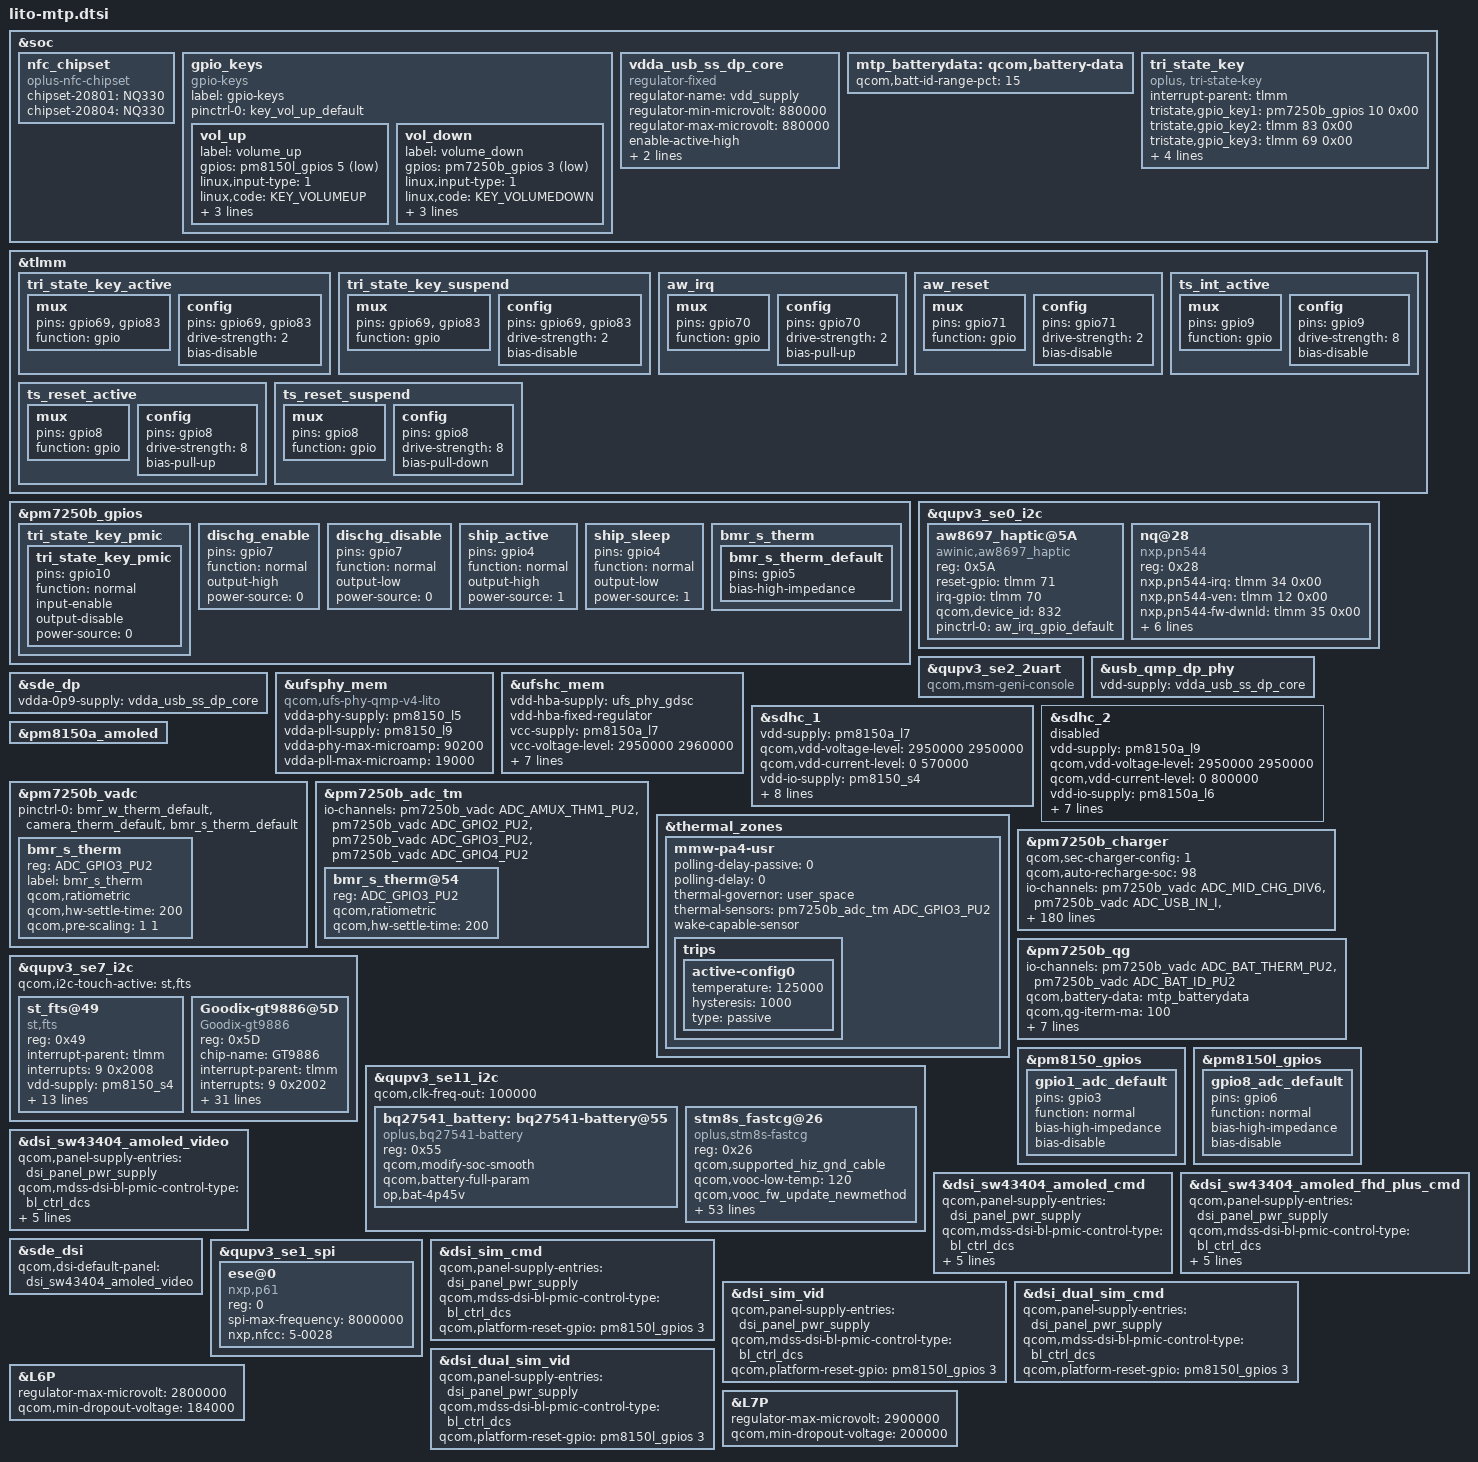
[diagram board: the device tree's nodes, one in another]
#include <dt-bindings/gpio/gpio.h>
#include "lito-audio-overlay.dtsi"
#include "lito-pmic-overlay.dtsi"
#include "lito-sde-display.dtsi"
#include "lito-thermal-overlay.dtsi"
#include "lito-20801-sensor.dtsi"

&soc {
    //add for nfc_chipset
	nfc_chipset {
		compatible = "oplus-nfc-chipset";
		chipset-20801 = "NQ330";
		chipset-20804 = "NQ330";
	};
	gpio_keys {
		compatible = "gpio-keys";
		label = "gpio-keys";

		pinctrl-names = "default";
		pinctrl-0 = <&key_vol_up_default>;

		vol_up {
			label = "volume_up";
			gpios = <&pm8150l_gpios 5 GPIO_ACTIVE_LOW>;
			linux,input-type = <1>;
			linux,code = <KEY_VOLUMEUP>;
			gpio-key,wakeup;
			debounce-interval = <15>;
			linux,can-disable;
		};

               vol_down {
                        label = "volume_down";
                        gpios = <&pm7250b_gpios  3 GPIO_ACTIVE_LOW>;
                        linux,input-type = <1>;
                        linux,code = <KEY_VOLUMEDOWN>;
                        gpio-key,wakeup;
                        debounce-interval = <15>;
                        linux,can-disable;
                };

	};

	vdda_usb_ss_dp_core: vdda_usb_ss_dp_core {
		compatible = "regulator-fixed";
		regulator-name = "vdd_supply";
		regulator-min-microvolt = <880000>;
		regulator-max-microvolt = <880000>;
		enable-active-high;
		gpio = <&pm8150l_gpios 12 GPIO_ACTIVE_HIGH>;
		pinctrl-names = "default";
		pinctrl-0 = <&usb_eldo13>;
	};

	mtp_batterydata: qcom,battery-data {
		qcom,batt-id-range-pct = <15>;
		#include "qg-batterydata-alium-3600mah.dtsi"
		#include "qg-batterydata-atl466271_3300mAh.dtsi"
	};
	
	tri_state_key:tri_state_key {
		compatible = "oplus, tri-state-key";
		status = "ok";
		interrupt-parent = <&tlmm>;
		tristate,gpio_key1 = <&pm7250b_gpios 10 0x00>;
		tristate,gpio_key2 = <&tlmm 83 0x00>;
		tristate,gpio_key3 = <&tlmm 69 0x00>;
		pinctrl-names =
					"pmx_tri_state_key_active",
					"pmx_tri_state_key_suspend";
		pinctrl-0 = <&tri_state_key_active &tri_state_key_pmic>;
		pinctrl-1 = <&tri_state_key_suspend &tri_state_key_pmic>;
	};
};


&tlmm{
	tri_state_key_active: tri_state_key_active {
		mux {
			pins = "gpio69", "gpio83";
			function = "gpio";
		};
		config {
			pins = "gpio69", "gpio83";
			drive-strength = <2>;
			bias-disable;
		};
	};

	tri_state_key_suspend: tri_state_key_suspend {
		mux {
			pins = "gpio69", "gpio83";
			function = "gpio";
		};
		config {
			pins = "gpio69", "gpio83";
			drive-strength = <2>;
			bias-disable;
		};
	};
};

&pm7250b_gpios {
	tri_state_key_pmic {
		tri_state_key_pmic: tri_state_key_pmic {
			pins = "gpio10";
			function = "normal";
			input-enable;
			output-disable;
			power-source = <0>;
		};
	};

        dischg_enable: dischg_enable {
                        pins = "gpio7";
                        function = "normal";
                        output-high;
                        power-source = <0>;
        };

        dischg_disable: dischg_disable {
                        pins = "gpio7";
                        function = "normal";
                        output-low;
                        power-source = <0>;
        };

        ship_active: ship_active {
                        pins = "gpio4";
                        function = "normal";
                        output-high;
                        power-source = <1>;     /* 1.8V input supply */
        };

        ship_sleep: ship_sleep {
                        pins = "gpio4";
                        function = "normal";
                        output-low;
                        power-source = <1>;     /* 1.8V input supply */
        };
};


/*for aw haptic start*/

&tlmm {
       aw_irq: aw_irq {
       mux {
            pins = "gpio70";
            function = "gpio";
       };
       config {
               pins = "gpio70";
               drive-strength = <2>;
               bias-pull-up;
       };
    };
    aw_reset: aw_reset {
       mux {
	            pins = "gpio71";
	            function = "gpio";
	       };
	      config {
	              pins = "gpio71";
	              drive-strength = <2>;
	              bias-disable;
	      };
      };
};
&qupv3_se0_i2c {
	status = "ok";
	aw8697_haptic@5A {
		compatible = "awinic,aw8697_haptic";
		reg = <0x5A>;
		reset-gpio = <&tlmm 71 0x00>;
		irq-gpio = <&tlmm 70 0x00>;
		pinctrl-names = "default";
		qcom,device_id = <832>;

		pinctrl-0 = <&aw_irq_gpio_default>;
		status = "okay";
	};
};

&qupv3_se2_2uart {
    compatible = "qcom,msm-geni-console";
};

&usb_qmp_dp_phy {
	vdd-supply = <&vdda_usb_ss_dp_core>;
};

&sde_dp {
	vdda-0p9-supply = <&vdda_usb_ss_dp_core>;
};

&ufsphy_mem {
	compatible = "qcom,ufs-phy-qmp-v4-lito";

	vdda-phy-supply = <&pm8150_l5>;
	vdda-pll-supply = <&pm8150_l9>;
	vdda-phy-max-microamp = <90200>;
	vdda-pll-max-microamp = <19000>;

	status = "ok";
};

&ufshc_mem {
	vdd-hba-supply = <&ufs_phy_gdsc>;
	vdd-hba-fixed-regulator;
	vcc-supply = <&pm8150a_l7>;
	vcc-voltage-level = <2950000 2960000>;
	vccq2-supply = <&pm8150_s4>;
	vcc-max-microamp = <800000>;
	vccq2-max-microamp = <800000>;

	qcom,vddp-ref-clk-supply = <&pm8150_l9>;
	qcom,vddp-ref-clk-max-microamp = <100>;
	qcom,vddp-ref-clk-min-uV = <1152000>;
	qcom,vddp-ref-clk-max-uV = <1200000>;
	status = "ok";
};

&sdhc_1 {
	vdd-supply = <&pm8150a_l7>;
	qcom,vdd-voltage-level = <2950000 2950000>;
	qcom,vdd-current-level = <0 570000>;

	vdd-io-supply = <&pm8150_s4>;
	qcom,vdd-io-always-on;
	qcom,vdd-io-lpm-sup;
	qcom,vdd-io-voltage-level = <1800000 1800000>;
	qcom,vdd-io-current-level = <0 325000>;

	pinctrl-names = "active", "sleep";
	pinctrl-0 = <&sdc1_clk_on &sdc1_cmd_on &sdc1_data_on
					&sdc1_rclk_on>;
	pinctrl-1 = <&sdc1_clk_off &sdc1_cmd_off &sdc1_data_off
					&sdc1_rclk_off>;

	status = "ok";
};

&sdhc_2 {
	vdd-supply = <&pm8150a_l9>;
	qcom,vdd-voltage-level = <2950000 2950000>;
	qcom,vdd-current-level = <0 800000>;

	vdd-io-supply = <&pm8150a_l6>;
	qcom,vdd-io-voltage-level = <1800000 2950000>;
	qcom,vdd-io-current-level = <0 22000>;

	pinctrl-names = "active", "sleep";
	pinctrl-0 = <&sdc2_clk_on  &sdc2_cmd_on &sdc2_data_on &sdc2_cd_on>;
	pinctrl-1 = <&sdc2_clk_off &sdc2_cmd_off &sdc2_data_off &sdc2_cd_off>;

	cd-gpios = <&tlmm 69 GPIO_ACTIVE_LOW>;

	status = "disabled";
};

&pm8150a_amoled {
	status = "ok";
};

&pm7250b_vadc {
	pinctrl-0 = <
		&bmr_w_therm_default
		&camera_therm_default
		&bmr_s_therm_default
	>;

	bmr_s_therm {
		reg = <ADC_GPIO3_PU2>;
		label = "bmr_s_therm";
		qcom,ratiometric;
		qcom,hw-settle-time = <200>;
		qcom,pre-scaling = <1 1>;
	};
};

&pm7250b_gpios {
	bmr_s_therm {
		bmr_s_therm_default: bmr_s_therm_default {
			pins = "gpio5";
			bias-high-impedance;
		};
	};
};

&pm7250b_adc_tm {
	io-channels = <&pm7250b_vadc ADC_AMUX_THM1_PU2>,
			<&pm7250b_vadc ADC_GPIO2_PU2>,
			<&pm7250b_vadc ADC_GPIO3_PU2>,
			<&pm7250b_vadc ADC_GPIO4_PU2>;

	bmr_s_therm@54 {
		reg = <ADC_GPIO3_PU2>;
		qcom,ratiometric;
		qcom,hw-settle-time = <200>;
	};
};

&thermal_zones {
	mmw-pa4-usr {
		polling-delay-passive = <0>;
		polling-delay = <0>;
		thermal-governor = "user_space";
		thermal-sensors = <&pm7250b_adc_tm ADC_GPIO3_PU2>;
		wake-capable-sensor;
		trips {
			active-config0 {
				temperature = <125000>;
				hysteresis = <1000>;
				type = "passive";
			};
		};
	};
};

&pm7250b_charger {
        status = "ok";
        qcom,sec-charger-config = <1>;
        qcom,auto-recharge-soc = <98>;
        io-channels = <&pm7250b_vadc ADC_MID_CHG_DIV6>,
                      <&pm7250b_vadc ADC_USB_IN_I>,
                      <&pm7250b_vadc ADC_SBUx>,
                      <&pm7250b_vadc ADC_VPH_PWR>,
		      <&pm7250b_vadc ADC_CHG_TEMP>,
		      <&pm7250b_vadc ADC_DIE_TEMP>,
		      <&pm7250b_vadc ADC_AMUX_THM3_PU2>,
                      <&pm7250b_vadc ADC_USB_IN_V_16>,
		      <&pm8150l_vadc ADC_GPIO3_PU2>,
 		      <&pm8150_vadc ADC_GPIO1_PU1>,
 		      <&pm8150l_vadc ADC_GPIO2_PU1>;

        io-channel-names = "mid_voltage",
                           "usb_in_current",
                           "sbux_res",
                           "vph_voltage",
                           "chg_temp",
                           "die_temp",
                           "conn_temp",
                           "usb_in_voltage",
			   "skin_therm",
                           "usb_temp_l",
                           "usb_temp_r";

        qcom,battery-data = <&mtp_batterydata>;
        //qcom,step-charging-enable;
        //qcom,sw-jeita-enable;
        //qcom,wd-bark-time-secs = <16>;
        //qcom,suspend-input-on-debug-batt;
        //qcom,fcc-stepping-enable;
        qcom,smb-internal-pull-kohm = <0>;
        op,low-voltage-charger;
};



/*&pm7250b_charger {
	status = "ok";
	io-channels = <&pm7250b_vadc ADC_USB_IN_V_16>,
		      <&pm7250b_vadc ADC_USB_IN_I>,
		      <&pm7250b_vadc ADC_CHG_TEMP>,
		      <&pm7250b_vadc ADC_DIE_TEMP>,
		      <&pm7250b_vadc ADC_AMUX_THM3_PU2>,
		      <&pm7250b_vadc ADC_SBUx>,
		      <&pm7250b_vadc ADC_VPH_PWR>,
		      <&pm7250b_vadc ADC_AMUX_THM1_PU2>;
	io-channel-names = "usb_in_voltage",
			   "usb_in_current",
			   "chg_temp",
			   "die_temp",
			   "conn_temp",
			   "sbux_res",
			   "vph_voltage",
			   "skin_temp";
	qcom,battery-data = <&mtp_batterydata>;
	qcom,sec-charger-config = <1>;
	qcom,auto-recharge-soc = <98>;
	qcom,step-charging-enable;
	qcom,sw-jeita-enable;
	qcom,charger-temp-max = <800>;
	qcom,smb-temp-max = <800>;
	qcom,suspend-input-on-debug-batt;
	qcom,fcc-stepping-enable;
	qcom,fcc-step-delay-ms = <100>;
	qcom,fcc-step-size-ua = <100000>;
	qcom,smb-internal-pull-kohm = <0>;
	qcom,en-skin-therm-mitigation;
	qcom,hvdcp3-standalone-config;
};
*/

&pm7250b_qg {
	status = "ok";
	io-channels = <&pm7250b_vadc ADC_BAT_THERM_PU2>,
		      <&pm7250b_vadc ADC_BAT_ID_PU2>;
	io-channel-names = "batt-therm",
			   "batt-id";
	qcom,battery-data = <&mtp_batterydata>;
	qcom,qg-iterm-ma = <100>;
	qcom,hold-soc-while-full;
	qcom,linearize-soc;
	qcom,cl-feedback-on;
	qcom,tcss-enable;
	qcom,fvss-enable;
	qcom,fvss-vbatt-mv = <3300>;
	qcom,bass-enable;
};

&qupv3_se7_i2c {
	#address-cells = <1>;
	#size-cells = <0>;

	status = "ok";
	qcom,i2c-touch-active = "st,fts";

	st_fts@49 {
		compatible = "st,fts";
		reg = <0x49>;
		interrupt-parent = <&tlmm>;
		interrupts = <9 0x2008>;
		vdd-supply = <&pm8150_s4>;
		avdd-supply = <&pm8150_l13>;
		pinctrl-names = "pmx_ts_active", "pmx_ts_suspend";
		pinctrl-0 = <&ts_active>;
		pinctrl-1 = <&ts_int_suspend &ts_reset_suspend>;
		st,irq-gpio = <&tlmm 9 0x2008>;
		st,reset-gpio = <&tlmm 8 0x00>;
		st,regulator_dvdd = "vdd";
		st,regulator_avdd = "avdd";
		st,x-flip = <1>;
		st,y-flip = <1>;
		st,power_on_suspend;
		panel = <&dsi_sw43404_amoled_cmd &dsi_sw43404_amoled_video
			 &dsi_sw43404_amoled_fhd_plus_cmd>;
	};
};

&qupv3_se7_i2c {
        status = "ok";
        Goodix-gt9886@5D {
                compatible = "Goodix-gt9886";
                reg = <0x5D>;
                chip-name = "GT9886";

                /* Interrupt && Irq-gpio */
                interrupt-parent = <&tlmm>;
                interrupts = <9 0x2002>;

                /* Power Config */
                vdd_2v8-supply = <&pm8150_l13>;
                vdd_2v8_volt = <3008000>;
		enable1v8_gpio = <&pm8150l_gpios 1 GPIO_ACTIVE_LOW>;

               	/* Other HW Resource */
                irq-gpio = <&tlmm 9 0x2002>;
                reset-gpio = <&tlmm 8 0x1>;
                pinctrl-names = "pin_set_high", "pin_set_low";
                pinctrl-0 = <&ts_int_active &ts_reset_active>;
                pinctrl-1 = <&ts_reset_suspend>;

                touchpanel,max-num-support = <10>;
                touchpanel,tx-rx-num = <15 34>;
                touchpanel,panel-coords = <1080 2400>;
                touchpanel,display-coords = <1080 2400>;

		tp_type = <8>;
		platform_support_project = <20801 20804>;
                platform_support_project_dir = <20801 20801>;
                platform_support_project_commandline = "default_commandline", "default_commandline";

                /* SW Support Feature Control */
                black_gesture_support;
                game_switch_support;
                fw_edge_limit_support;
		pressure_report_support;
		charger_pump_support;
		smart_gesture_support;
                fw_update_app_support;
                fingerprint_underscreen_support;
                esd_handle_support;
		register-is-16bit;
		disable_suspend_irq_handler_support;
		irq_need_dev_resume_ok;

				/*
                 *Virtual Key Config:
                 *1:touchpanel,button-type: <virtualkey_type  supportted_button-map>
                 *virtualkey_type:
                 *Type 1: using board_properties
                 *Type 2: using same IC (button zone&& touch zone are seprate)
                 *Type 3: using diffrent IC (button zone&& touch zone are seprate)
                 *Type 4: No need of virtual key process
                 *supportted_button-map:select|menu|home|back
                 *
                 *2:touchpanel,button-map
                 *type (X1,Y1)(X2,Y2)(X3,Y3)(Width_X,Hight_Y)--Only when button-type is 0
                 */
                touchpanel,button-type = <4>;
                touchpanel.button-TRx = <0 0>;

	};
};

&qupv3_se11_i2c {
        status = "ok";
        qcom,clk-freq-out = <100000>;
        bq27541_battery:bq27541-battery@55 {
                status = "ok";
                compatible = "oplus,bq27541-battery";
                reg = <0x55>;
                qcom,modify-soc-smooth;
                qcom,battery-full-param;//only for wite battery full param in guage dirver probe on 7250 platform
                op,bat-4p45v;
        };

        stm8s_fastcg@26{
                status = "okay";
                compatible = "oplus,stm8s-fastcg";
                reg = <0x26>;
		qcom,supported_hiz_gnd_cable;

                qcom,vooc-low-temp = <120>;
		//qcom,oplus_batt_4400mv;
                qcom,vooc_fw_update_newmethod;
                qcom,vooc-high-temp = <430>;
                qcom,vooc-low-soc = <1>;
                qcom,vooc-high-soc = <90>;
                qcom,vooc-fw-type = <0x27>;

                qcom,vooc_multistep_adjust_current_support;
                qcom,vooc_multistep_initial_batt_temp = <310>;
                qcom,vooc_strategy_normal_current = <0x06>;
                qcom,vooc-normal-to-little-cool-current = <0x05>;
                qcom,vooc_batt_over_high_temp = <440>;
                qcom,vooc_batt_over_low_temp = <45>;
                qcom,vooc_over_high_or_low_current = <0x0>;

                qcom,vooc_strategy1_batt_high_temp0 = <425>;
                qcom,vooc_strategy1_batt_high_temp1 = <430>;
                qcom,vooc_strategy1_batt_high_temp2 = <435>;
                qcom,vooc_strategy1_batt_low_temp2 = <420>;
                qcom,vooc_strategy1_batt_low_temp1 = <415>;
                qcom,vooc_strategy1_batt_low_temp0 = <400>;

                qcom,vooc_strategy1_high_current0 = <0x04>;//4A
                qcom,vooc_strategy1_high_current1 = <0x03>;//3A
                qcom,vooc_strategy1_high_current2 = <0x02>;//2A
                qcom,vooc_strategy1_low_current2 = <0x03>;//3A
                qcom,vooc_strategy1_low_current1 = <0x04>;//4A
                qcom,vooc_strategy1_low_current0 = <0x04>;//4A

                qcom,vooc_strategy2_batt_up_temp1 = <375>;
                qcom,vooc_strategy2_batt_up_down_temp2 = <380>;
                qcom,vooc_strategy2_batt_up_temp3 = <390>;
                qcom,vooc_strategy2_batt_up_down_temp4 = <400>;
                qcom,vooc_strategy2_batt_up_temp5 = <410>;
                qcom,vooc_strategy2_batt_up_temp6 = <415>;
                qcom,vooc_strategy2_high0_current = <0x05>;
                qcom,vooc_strategy2_high1_current = <0x04>;
                qcom,vooc_strategy2_high2_current = <0x03>;
                qcom,vooc_strategy2_high3_current = <0x02>;


                pinctrl-names = "switch1_act_switch2_act", "switch1_sleep_switch2_sleep",
                                                "switch1_act_switch3_act", "switch1_sleep_switch3_sleep",
                                                "switch1_act_switch2_sleep", "switch1_sleep_switch2_act",
                                                "clock_active","clock_sleep",
                                                "data_active","data_sleep",
                                                "reset_active","reset_sleep";
                pinctrl-0 = <&charging_switch1_active>;
                pinctrl-1 = <&charging_switch1_sleep >;
                pinctrl-2 = <&charging_switch1_active>;
                pinctrl-3 = <&charging_switch1_sleep >;
                pinctrl-4 = <&charging_switch1_active>;
                pinctrl-5 = <&charging_switch1_sleep>;
                pinctrl-6 = <&charging_clock_active >;
                pinctrl-7 = <&charging_clock_sleep >;
                pinctrl-8 = <&charging_data_active >;
                pinctrl-9 = <&charging_data_sleep >;
                pinctrl-10 = <&charging_reset_active >;
                pinctrl-11 = <&charging_reset_sleep >;

                qcom,charging_switch1-gpio = <&tlmm 4 0x00>;
		qcom,charging_switch1_ctr1-gpio = <&tlmm 126 0x00>;
                //qcom,charging_switch2-gpio = <&tlmm 113 0x00>;
                //qcom,charging_switch3-gpio = <&tlmm 126 0x00>;

                qcom,charging_reset-gpio = <&tlmm 24 0x00>;
                qcom,charging_clock-gpio = <&tlmm 44 0x00>;
                qcom,charging_data-gpio = <&tlmm 45 0x00>;
		qcom,parse_fw_from_dt;
		vooc,firmware_data = [
			00 88 82 00 9D 30 82 00 9E 96 82 00 9E 96 82 00 
			9E 96 82 00 9E 96 82 00 9B 90 82 00 9E 96 82 00 
			9E 7D 20 88 82 00 9E 96 82 00 9E 96 82 00 9E 96 
			82 00 9E 96 82 00 9E 96 82 00 9E 96 82 00 9E 96 
			82 00 96 BD 40 88 82 00 9E 96 82 00 9E 96 82 00 
			9E 96 82 00 9E 96 82 00 9E 96 82 00 9E 96 82 00 
			9E 96 82 00 9E 96 60 88 82 00 9E 96 82 00 9E 96 
			82 00 9E 96 82 00 9E 96 82 00 9E 96 82 00 9E 96 
			82 00 9E 96 82 00 9E 96 80 88 C6 00 77 A1 08 24 
			17 CD 9E 57 B7 00 C6 00 77 5F 97 B6 00 D7 00 56 
			C6 00 77 4C C7 00 77 81 C6 00 A0 88 77 A1 08 27 
			03 CC 89 A9 CD 9D 77 C6 00 56 A1 01 26 41 C6 00 
			57 26 3C C6 00 58 A1 01 26 35 C6 00 C0 88 5A 48 
			48 88 C6 00 59 48 48 48 B7 01 84 BA 01 B7 00 C6 
			00 5B 48 BA 00 CA 00 5C C7 00 79 35 09 00 E0 88 
			77 C6 00 42 26 03 CC 89 A9 C6 00 42 4A C7 00 42 
			CC 89 A9 C6 00 56 26 33 C6 00 57 A1 01 26 2C C6 
			00 89 00 58 A1 01 26 25 C6 00 5A 48 48 88 C6 00 
			59 48 48 48 B7 01 84 BA 01 B7 00 C6 00 5B 48 BA 
			00 CA 20 89 00 5C C7 00 79 35 09 00 77 20 7E C6 
			00 57 B7 00 A1 01 26 3C C6 00 58 26 37 C6 00 59 
			A1 01 26 30 40 89 C6 00 5B 48 48 88 C6 00 5A 48 
			48 48 B7 01 84 BA 01 B7 00 C6 00 5C 48 BA 00 CA 
			00 5D C7 00 79 35 60 89 09 00 77 C6 00 42 27 07 
			C6 00 42 4A C7 00 42 81 3D 00 26 32 C6 00 58 A1 
			01 26 2B C6 00 59 A1 01 80 89 26 24 C6 00 5B 48 
			48 88 C6 00 5A 48 48 48 B7 01 84 BA 01 B7 00 C6 
			00 5C 48 BA 00 CA 00 5D C7 00 A0 89 79 35 09 00 
			77 81 CD 8F 80 C6 00 78 27 03 CC 8E B9 72 5F 00 
			48 72 5F 00 49 72 5F 00 4A 72 5F 00 C0 89 4B 72 
			5F 00 4C 72 5F 00 4D 72 5F 00 4E C6 00 81 A1 02 
			26 10 C6 00 79 4E A4 F0 C7 00 82 35 01 00 E0 89 
			4A CC 8E B9 C6 00 81 A1 01 26 10 C6 00 79 CA 00 
			82 C7 00 82 35 01 00 4A CC 8E B9 C6 00 83 A1 05 
			00 8A 26 2D C6 00 4F C7 00 48 C6 00 50 C7 00 49 
			C6 00 51 C7 00 4A C6 00 52 C7 00 4B C6 00 53 C7 
			00 4C 20 8A C6 00 54 C7 00 4D C6 00 55 C7 00 4E 
			CC 8E B9 C6 00 83 A1 04 26 12 C6 00 79 5F 97 CD 
			99 89 CF 00 40 8A 60 35 01 00 4A CC 8E B9 C6 00 
			83 A1 03 26 1E C6 00 79 5F 97 4F 02 90 CE 00 60 
			BF 00 51 02 BA 00 60 8A 01 51 90 CF 00 60 35 01 
			00 4A CC 8E B9 C6 00 83 A1 02 26 22 C6 00 79 5F 
			97 CD 99 91 90 CE 00 60 80 8A BF 00 51 01 BA 01 
			01 BA 00 01 51 90 CF 00 60 35 01 00 4A CC 8E B9 
			C6 00 83 A1 01 26 2D C6 00 79 A0 8A 90 5F 90 97 
			CE 00 60 90 BF 00 01 BA 01 02 CF 00 60 CD 9E 2C 
			35 01 00 4A CE 00 3A C3 00 60 27 03 C0 8A CC 8E 
			B9 35 01 00 86 CC 8E B9 C6 00 84 27 5D C6 00 84 
			90 5F 90 97 AE 00 07 BF 00 93 CD 99 37 1C E0 8A 
			00 10 90 93 72 A9 FF F9 90 F6 C7 00 48 90 93 72 
			A9 FF FA 90 F6 C7 00 49 90 93 72 A9 FF FB 90 F6 
			00 8B C7 00 4A 90 93 72 A9 FF FC 90 F6 C7 00 4B 
			90 93 72 A9 FF FD 90 F6 C7 00 4C 90 93 72 A9 FF 
			FE 90 20 8B F6 C7 00 4D 5A F6 C7 00 4E CC 8E B9 
			C6 00 79 A1 09 26 11 72 5F 00 81 72 5F 00 83 4F 
			CD 9D 99 35 40 8B 01 00 76 81 72 5F 00 81 72 5F 
			00 83 C6 00 79 27 2B 4A 27 2B 4A 26 03 CC 8D 55 
			4A 26 03 CC 8D 9B 60 8B 4A 26 03 CC 8E 32 4A 26 
			03 CC 8E 7B A0 07 26 03 CC 8E 89 4A 26 03 CC 8E 
			A9 CC 8E B9 CC 8F 80 C6 80 8B 00 42 27 03 CC 8C 
			AA C6 00 44 A1 01 27 03 CD 8F 80 C6 00 75 C7 00 
			48 C6 00 97 27 24 C6 00 9B 26 A0 8B 1F 35 01 00 
			49 35 01 00 4A 35 01 00 4B 72 5F 00 4C 35 01 00 
			4D 72 5F 00 4E 35 01 00 9B CC 8E B9 C0 8B CE 00 
			5E A3 0D 40 2E 03 CC 8C 98 CE 00 5E 1C F2 C0 90 
			AE 00 10 CD 99 55 A3 00 3E 2F 03 AE 00 3D E0 8B 
			C6 00 96 27 13 C6 00 9C 26 0E A3 00 3A 2E 09 AE 
			00 3A 35 01 00 9C 20 16 C6 00 95 27 11 C6 00 9D 
			00 8C 26 0C A3 00 39 2E 07 AE 00 39 35 01 00 9D 
			9F CD 9E 26 A4 01 C7 00 49 9F CD 9E 27 A4 01 C7 
			00 4A 20 8C 9F 47 47 47 A4 01 C7 00 4B 9F 47 47 
			A4 01 C7 00 4C 9F 47 A4 01 C7 00 4D 9F A4 01 C7 
			00 4E CD 9A 40 8C F9 A1 00 26 08 C6 00 8B 26 03 
			CC 8E B9 4F CD 9D 99 35 01 00 8B C6 00 94 26 1F 
			35 01 00 49 35 01 60 8C 00 4A 35 01 00 4B 35 01 
			00 4C 35 01 00 4D 72 5F 00 4E 35 01 00 94 CC 8E 
			B9 72 5F 00 49 72 5F 00 80 8C 4A 72 5F 00 4B 35 
			01 00 4C 72 5F 00 4D 35 01 00 4E 72 5F 00 94 CC 
			8E B9 CE 00 5E A3 0B B8 2F 03 A0 8C CC 8E B9 72 
			5F 00 48 CC 8E B9 C6 00 8B 27 27 C6 00 94 26 17 
			35 01 00 48 35 01 00 49 35 01 00 4D C0 8C 35 01 
			00 4E 35 01 00 94 CC 8E B9 35 01 00 4B 72 5F 00 
			94 CC 8E B9 C6 00 8E 27 26 35 01 00 48 35 E0 8C 
			01 00 49 35 01 00 4A 35 01 00 4B 35 01 00 4C 35 
			01 00 4D 35 01 00 4E C6 00 8E 4A C7 00 8E CC 8E 
			00 8D B9 CE 00 5E A3 0D 4C 2E 03 5F 20 0D CE 00 
			5E 1C F2 B4 90 AE 00 0A CD 99 55 9F CD 9E 25 A4 
			01 C7 20 8D 00 48 9F CD 9E 26 A4 01 C7 00 49 9F 
			CD 9E 27 A4 01 C7 00 4A 9F 47 47 47 A4 01 C7 00 
			4B 9F 47 47 40 8D A4 01 C7 00 4C 9F 47 A4 01 C7 
			00 4D 9F A4 01 C7 00 4E CC 8E B9 C6 00 42 26 0E 
			C6 00 44 A1 02 27 60 8D 03 CD 8F 80 35 01 00 48 
			35 03 00 00 A6 04 CD 98 20 C7 00 9A C6 00 9A A1 
			02 26 07 35 01 00 49 CC 80 8D 8E B9 C6 00 9A A1 
			01 26 0B 35 01 00 49 35 01 00 4A CC 8E B9 35 01 
			00 4A CC 8E B9 C6 00 42 26 4F A0 8D C6 00 44 A1 
			03 27 03 CD 8F 80 C6 00 97 27 13 72 5F 00 4B 72 
			5F 00 4C 72 5F 00 4D 72 5F 00 4E CC C0 8D 8E B9 
			C6 00 98 A1 01 26 13 72 5F 00 4B 72 5F 00 4C 35 
			01 00 4D 72 5F 00 4E CC 8E B9 72 5F 00 4B E0 8D 
			72 5F 00 4C 35 01 00 4D 35 01 00 4E CC 8E B9 C6 
			00 91 CD 9E 20 A4 01 C7 00 49 C6 00 91 4E A4 0F 
			00 8E A4 01 C7 00 4A C6 00 91 44 44 44 A4 01 C7 
			00 4B C6 00 91 44 44 A4 01 C7 00 4C C6 00 91 44 
			A4 01 20 8E C7 00 4D C6 00 91 A4 01 C7 00 4E 72 
			5F 00 8E CC 8E B9 C6 00 43 27 11 C6 00 43 4A C7 
			00 43 35 01 40 8E 00 4A 35 01 00 4E 20 71 C6 00 
			42 27 08 C6 00 75 C7 00 48 20 E9 C6 00 44 A1 04 
			27 03 CD 8F 80 35 60 8E 01 00 45 72 5F 00 46 35 
			01 00 47 C6 00 75 C7 00 48 35 01 00 4A 35 01 00 
			4E 20 3E 35 03 00 81 35 80 8E 01 00 49 35 01 00 
			4B 20 30 C6 00 40 27 2B C6 00 88 27 26 C6 00 40 
			4A C7 00 40 35 06 00 83 CD 9E A0 8E 77 C7 00 8A 
			CD 97 77 20 10 35 07 00 84 35 08 00 85 35 01 00 
			4A 35 01 00 4B C6 00 78 5F 97 D6 00 C0 8E 45 CD 
			9D EB C6 00 78 4C C7 00 78 C6 00 78 A1 0A 24 03 
			CC 8F 7F A6 04 CD 9C 30 CD 9D DE 72 5F 00 E0 8E 
			78 72 5F 00 77 72 5F 00 7A 72 5F 00 73 C6 00 81 
			27 08 C6 00 81 4A C7 00 81 81 C6 00 83 27 08 C6 
			00 8F 00 83 4A C7 00 83 81 C6 00 84 27 0F C6 00 
			84 4A C7 00 84 C6 00 85 4A C7 00 85 81 C6 00 79 
			4A 27 20 8F 4B 4A 27 08 4A 27 45 4A 27 23 20 4A 
			C6 00 9A A1 01 26 4C C6 00 87 A1 01 26 05 A6 01 
			CD 9D 99 72 40 8F 5F 00 9A C6 00 42 26 37 35 03 
			00 44 81 C6 00 42 26 0F C6 00 48 27 06 35 02 00 
			44 20 04 35 04 00 60 8F 44 35 01 00 88 CD 9E 77 
			C7 00 89 81 C6 00 42 26 0E 35 01 00 44 81 C6 00 
			42 26 04 35 04 00 44 81 80 8F C6 00 99 A1 02 27 
			0F C6 00 99 A1 01 26 05 35 02 00 99 81 CD 9E 12 
			81 CD 98 DF CD 98 E4 52 04 4F A0 8F 6B 03 6B 02 
			6B 01 3F 0B 3F 0C 3F 0D 3F 0E 6B 04 3F 0F 3F 0A 
			AE 17 70 CF 00 3C AE 03 84 CF 00 3E C0 8F 20 28 
			A6 0A 97 B6 00 42 41 B7 00 C6 00 8E 26 0E C6 00 
			90 B7 01 C6 00 92 CD 9A B7 C7 00 8E CD 9E E0 8F 
			38 CD 9E 38 AE 17 70 CF 00 6A CD 9E 87 CE 00 6A 
			26 43 A6 58 CD 95 23 B7 00 C6 00 8B 26 E0 B6 00 
			00 90 A1 07 26 0A 4F CD 9D 99 35 01 00 8B 20 D0 
			3D 00 26 05 CD 9E 12 20 C7 A1 06 26 06 35 3B 00 
			00 20 20 90 AA A1 02 26 06 35 19 00 00 20 A0 A1 
			01 26 93 35 14 00 00 20 96 CE 00 68 27 03 CC 90 
			F7 C6 00 7C 40 90 CD 9A 30 BF 08 C6 00 8B 27 03 
			CC 90 E8 A3 F8 30 2E 12 7B 01 4C 6B 01 7B 01 A1 
			04 25 0A A6 54 CD 60 90 9C C0 20 03 4F 6B 01 BE 
			08 A3 1B 59 2F 10 B6 0D 4C B7 0D A1 08 25 09 A6 
			59 CD 9C C0 20 02 3F 0D 80 90 BE 08 A3 01 F4 2E 
			08 CE 00 5E A3 11 31 2E 0F BE 08 A3 03 84 2E 18 
			CE 00 5E A3 11 81 2F 10 B6 0E A0 90 4C B7 0E A1 
			06 25 09 A6 5A CD 9C C0 20 02 3F 0E C6 00 41 A1 
			02 26 2E BE 08 A3 04 B0 2E 27 CE 00 C0 90 5E A3 
			11 8B 2F 05 A6 5A CD 9C C0 CE 00 5E A3 11 81 2F 
			12 7B 02 4C 6B 02 7B 02 A1 06 25 0A A6 5A E0 90 
			CD 9C C0 20 03 4F 6B 02 CD 9E 38 CD 9E 38 AE 03 
			E8 CF 00 68 CC 8F EA CE 00 66 26 36 C6 00 42 26 
			00 91 31 C6 00 7D CD 9A 30 A3 00 60 2F 15 C6 00 
			8B 26 10 B6 0B 4C B7 0B A1 04 25 09 A6 5A CD 9C 
			C0 20 20 91 02 3F 0B CD 9E 38 CD 9E 38 AE 07 D0 
			CF 00 66 CC 8F EA CE 00 64 26 77 C6 00 7B CD 9A 
			30 CF 00 5E 40 91 C6 00 8B 26 5A CE 00 3E 27 08 
			CE 00 5E A3 10 69 2F 0B C6 00 92 A1 33 25 04 35 
			32 00 92 C6 00 8E 60 91 26 13 C6 00 90 B7 01 C6 
			00 8F B7 00 C6 00 92 CD 9A B7 C7 00 8E CE 00 5E 
			A3 11 8B 2F 05 A6 5A CD 80 91 9C C0 CE 00 5E A3 
			11 81 2F 12 7B 03 4C 6B 03 7B 03 A1 06 25 0A A6 
			5A CD 9C C0 20 03 4F 6B 03 CD A0 91 9E 38 CD 9E 
			38 AE 01 F4 CF 00 64 CC 8F EA CE 00 6E 27 03 CC 
			92 4D C6 00 7E CD 9A 30 BF 08 A3 01 C0 91 5F 2F 
			05 1C FF F6 BF 08 C6 00 8B 26 71 BE 08 A3 01 B3 
			2F 13 B6 0A 4C B7 0A A1 03 25 28 35 03 00 E0 91 
			0A 35 01 00 96 20 1E A3 01 A5 2F 15 3F 0A B6 0F 
			4C B7 0F A1 03 25 0E 35 03 00 0F 35 01 00 95 20 
			00 92 04 3F 0F 3F 0A 1C FF 8D A3 01 46 25 10 B6 
			0C 4C B7 0C A1 03 25 28 A6 5C CD 9C C0 20 21 3F 
			0C C6 20 92 00 41 A1 01 26 0D BE 08 A3 01 5F 2F 
			11 35 02 00 41 20 0B BE 08 A3 01 59 2E 04 35 01 
			00 41 CD 9E 40 92 38 CD 9E 38 AE 01 F4 CF 00 6E 
			CC 8F EA CE 00 70 26 33 C6 00 8B 26 18 CD 9A F9 
			A1 00 27 08 4F CD 60 92 9D 99 35 01 00 8B AE 03 
			20 CF 00 70 CC 8F EA 0D 04 26 09 A6 5D CD 95 23 
			A6 01 6B 04 AE 27 10 CF 80 92 00 70 CC 8F EA CE 
			00 6C 27 03 CC 8F EA CE 00 3C 26 0A C6 00 8B 26 
			05 A6 5A CD 9C C0 C6 00 73 26 A0 92 07 C6 00 99 
			A1 02 25 11 C6 00 76 27 07 A6 59 CD 9C C0 20 05 
			A6 54 CD 9C C0 C6 00 76 27 05 A6 59 C0 92 CD 9C 
			C0 AE 00 14 CF 00 6C CC 8F EA CD 9E 82 CD 99 96 
			CD 95 F9 CD 9B BB CD 99 EB CD 9D 07 4F CD E0 92 
			9C 83 4F CD 9B 60 4F CD 9B 30 A6 01 CD 9C 83 CD 
			9E 6B CD 9E 71 A1 00 27 F6 CD 9C F2 CD 9E 87 20 
			00 93 03 CD 9E 38 CD 9E 87 C6 00 73 27 03 CD 9E 
			12 C6 00 86 A1 01 26 07 C6 00 85 A1 01 27 05 C6 
			00 42 20 93 26 DF 35 01 00 87 CD 9B CD A6 52 CD 
			95 23 35 01 00 99 4D 26 03 CD 9E 12 CD 9E 87 A6 
			5E CD 95 23 40 93 A1 02 27 03 CD 9E 12 CD 9E 87 
			CD 9E 38 CD 9E 87 C6 00 82 CD 95 23 A1 02 27 03 
			CD 9E 12 CD 9E 87 60 93 C6 00 7F 26 12 35 08 00 
			7B 35 14 00 7C 35 2C 00 7D 35 06 00 7E 20 17 C6 
			00 7F A1 01 26 10 35 04 80 93 00 7B 35 10 00 7C 
			35 1C 00 7D 35 02 00 7E 35 01 00 80 CD 9E 87 C6 
			00 7B CD 9A 30 CF 00 5E CD 9E A0 93 38 C6 00 7E 
			CD 9A 30 A3 00 A0 2E 0C 35 28 00 91 35 28 00 92 
			35 01 00 98 CD 9E 38 C6 00 7D CD 9A C0 93 30 9F 
			A1 4C 25 10 35 14 00 8F 35 14 00 90 35 14 00 91 
			35 14 00 92 25 04 35 01 00 97 35 01 00 75 E0 93 
			20 14 CD 9E 87 C6 00 73 26 07 C6 00 99 A1 02 25 
			05 A6 54 CD 9C C0 CD 9E 43 A1 01 27 E5 CD 8F 97 
			00 94 5F 81 CD 98 DF B7 0A 45 00 0B BF 08 CD 9E 
			87 72 03 52 19 0B 72 12 52 11 72 02 52 11 FB 20 
			F0 CD 20 94 9E 87 72 14 52 11 72 10 52 11 CD 9E 
			87 72 01 52 17 FB CD 9E 87 35 AA 52 16 CD 9E 87 
			72 03 52 17 40 94 FB CD 9E 87 9D 9D C6 52 19 CD 
			9E 87 72 0F 52 17 FB B6 0A C7 52 16 C6 52 17 A4 
			84 A1 84 26 F7 9D 60 94 9D 9D 9D 72 10 52 11 72 
			01 52 17 FB CD 9E 87 35 AB 52 16 72 03 52 17 FB 
			CD 9E 87 B6 0B A1 03 25 80 94 4C C6 52 19 20 15 
			72 05 52 17 FB C6 52 16 92 C7 08 BE 08 5C BF 08 
			B6 0B 4A B7 0B B6 0B A1 04 24 A0 94 E5 72 05 52 
			17 FB 72 15 52 11 9B C6 52 16 92 C7 08 BE 08 5C 
			72 12 52 11 C6 52 16 F7 5C BF 08 9A C0 94 72 0D 
			52 17 FB C6 52 16 92 C7 08 20 47 A1 02 26 2B 72 
			16 52 11 9B C6 52 19 72 15 52 11 9A 72 05 E0 94 
			52 17 FB 9B 72 12 52 11 C6 52 16 92 C7 08 BE 08 
			5C BF 08 9A C6 52 16 92 C7 08 20 18 72 15 52 11 
			00 95 9B C6 52 19 72 12 52 11 9A 72 0D 52 17 FB 
			C6 52 16 92 C7 08 72 02 52 11 FB 72 17 52 11 CD 
			9E 87 20 95 CC 99 2F CD 98 AE 3B 00 0A B7 08 3F 
			0A CD 9E 87 72 5F 00 74 CD 9D 43 3F 09 20 34 C6 
			00 73 27 09 40 95 B6 08 A1 58 26 03 CD 9D DE CD 
			9E 87 C6 00 74 27 FB CD 9E 87 A6 06 B0 09 5F 41 
			B6 08 41 CD 99 81 60 95 9F A4 01 CD 9D C4 72 5F 
			00 74 B6 09 4C B7 09 B6 09 A1 07 25 C6 CD 9E 87 
			3F 09 20 16 A6 02 B0 09 80 95 5F 41 B6 00 41 CD 
			99 79 9F BA 0A B7 0A B6 09 4C B7 09 B6 09 A1 04 
			24 3E C6 00 73 27 09 B6 08 A1 A0 95 58 26 03 CD 
			9D DE CD 9E 87 C6 00 74 27 FB CD 9E 87 3D 09 26 
			06 CD 9D B7 CD 9E 61 72 5F 00 74 CD C0 95 9E 4D 
			B7 00 B6 09 A1 03 26 B2 C6 00 80 26 BE B6 00 C7 
			00 7F 20 B7 CD 9E 87 C6 00 74 27 FB CD 9E E0 95 
			87 CD 9D 66 72 5F 00 74 CD 9E 38 CD 9E 38 CD 9E 
			87 B6 0A 32 00 0A CC 99 33 5F CF 00 5E 72 5F 00 
			00 96 73 72 5F 00 74 72 5F 00 75 72 5F 00 76 72 
			5F 00 77 72 5F 00 45 35 01 00 46 35 01 00 47 72 
			5F 00 20 96 78 72 5F 00 79 72 5F 00 7A 72 5F 00 
			7B 72 5F 00 7C 72 5F 00 7D 72 5F 00 7E 72 5F 00 
			7F 72 5F 00 40 96 80 72 5F 00 95 72 5F 00 96 72 
			5F 00 81 72 5F 00 82 35 03 00 40 72 5F 00 83 72 
			5F 00 84 72 5F 00 60 96 85 CF 00 60 5A CF 00 3A 
			72 5F 00 86 72 5F 00 87 72 5F 00 88 72 5F 00 89 
			72 5F 00 8A 72 5F 00 8B 80 96 72 5F 00 8C 72 5F 
			00 8D 72 5F 00 8E 35 3B 00 8F 35 3B 00 90 35 3B 
			00 91 35 3B 00 92 35 01 00 41 A0 96 72 5F 00 93 
			72 5F 00 94 35 03 00 42 35 03 00 43 72 5F 00 99 
			35 04 00 44 72 5F 00 98 81 8A 84 A4 C0 96 BF 88 
			86 CD 98 D5 CD 98 DA 72 11 53 04 CE 00 62 27 09 
			CE 00 62 5A CF 00 62 20 1E AE 03 E8 CF 00 E0 96 
			62 CE 00 3C 27 07 CE 00 3C 5A CF 00 3C CE 00 3E 
			27 07 CE 00 3E 5A CF 00 3E CE 00 64 27 07 CE 00 
			00 97 64 5A CF 00 64 CE 00 66 27 07 CE 00 66 5A 
			CF 00 66 CE 00 68 27 07 CE 00 68 5A CF 00 68 CE 
			00 6A 20 97 27 07 CE 00 6A 5A CF 00 6A CE 00 6C 
			27 07 CE 00 6C 5A CF 00 6C CE 00 6E 27 07 CE 00 
			6E 5A CF 00 40 97 6E CE 00 70 27 07 CE 00 70 5A 
			CF 00 70 C6 00 8D 4C C7 00 8D C6 00 8D A1 C9 25 
			15 72 5F 00 8D C6 60 97 00 7A 27 08 4F CD 9D 99 
			35 01 00 73 35 01 00 7A CD 99 11 CD 99 06 80 C6 
			00 8A 5F 97 58 BF 00 C6 80 97 00 89 5F 97 4F 02 
			58 01 BA 01 01 BA 00 01 CF 00 3A C6 00 89 CD 9E 
			1F A4 01 C7 00 4A C6 00 89 CD A0 97 9E 20 A4 01 
			C7 00 50 C6 00 89 4E A4 0F A4 01 C7 00 4D C6 00 
			89 44 44 44 A4 01 C7 00 55 C6 00 89 C0 97 44 44 
			A4 01 C7 00 53 C6 00 89 44 A4 01 C7 00 52 C6 00 
			89 A4 01 C7 00 4C C6 00 8A CD 9E 1F A4 01 E0 97 
			C7 00 48 C6 00 8A CD 9E 20 A4 01 C7 00 51 C6 00 
			8A 4E A4 0F A4 01 C7 00 49 C6 00 8A 44 44 44 A4 
			00 98 01 C7 00 4F C6 00 8A 44 44 A4 01 C7 00 4E 
			C6 00 8A 44 A4 01 C7 00 54 C6 00 8A A4 01 C7 00 
			4B 81 20 98 CD 98 AE 3B 00 0A 45 00 0A CD 9A 74 
			BF 08 B6 0A CD 9A 74 BF 00 BE 08 72 B0 00 00 90 
			CE 00 5E 90 40 98 A3 0E 74 2E 08 35 12 00 00 A6 
			25 20 3C 90 CE 00 5E 90 A3 0E D8 2E 08 35 12 00 
			00 A6 24 20 2A 90 60 98 CE 00 5E 90 A3 0F A0 2E 
			08 35 11 00 00 A6 22 20 18 90 CE 00 5E 90 A3 10 
			04 2E 08 35 10 00 00 A6 80 98 21 20 06 35 10 00 
			00 A6 20 90 5F 61 B6 00 61 90 BF 00 B3 00 2E 03 
			4F 20 0F 90 97 BF 00 90 B3 00 A0 98 2E 04 A6 02 
			20 02 A6 01 32 00 0A CC 99 33 88 A6 08 20 00 88 
			7B 02 88 7B 02 89 1E 06 1F 04 5F 97 C0 98 FE 1F 
			06 85 84 81 89 1E 05 BF 08 20 00 1E 03 1F 05 85 
			5B 02 81 88 A6 00 20 0F 88 A6 04 20 0A 88 E0 98 
			A6 08 20 05 88 A6 0C 20 00 88 89 7B 04 88 7B 04 
			89 1E 08 1F 04 5F 97 1F 08 FE 1F 06 1E 08 5C 5C 
			00 99 FE 1F 08 85 84 81 89 1E 05 BF 00 1E 07 BF 
			02 20 16 89 1E 05 BF 04 1E 07 BF 06 20 0B 89 1E 
			05 BF 20 99 08 1E 07 BF 0A 20 00 1E 03 1F 07 85 
			5B 04 81 CD 99 1C 81 CD 98 C6 81 88 89 5E B6 01 
			42 89 1E 03 40 99 B6 00 42 72 FB 01 4F 02 89 1E 
			05 B6 01 42 72 FB 01 5B 06 84 81 5D 2B 06 90 5D 
			2B 0A 65 81 50 90 60 99 5D 2B 07 65 50 81 90 50 
			20 F9 90 50 20 EE CD 9D A9 02 B4 00 02 B4 01 02 
			81 4D 27 04 58 4A 26 FC 80 99 81 4D 27 04 57 4A 
			26 FC 81 58 58 58 58 58 58 58 58 58 58 58 58 81 
			3B 00 08 3F 08 35 01 00 8C 4F A0 99 CD 9C 83 CD 
			9D 88 20 2B 4F CD 9E 05 A6 01 CD 9C 30 A6 01 CD 
			9E 05 A6 01 CD 9C 30 4F CD 9E 05 A6 C0 99 02 CD 
			9C 30 A6 01 CD 9E 05 A6 03 CD 9C 30 B6 08 4C B7 
			08 B6 08 A1 0F 25 CF A6 01 CD 9B 60 A6 C8 E0 99 
			CD 9C 30 72 5F 00 8C 32 00 08 81 C6 50 05 AA 30 
			C7 50 05 C6 50 07 AA 30 C7 50 07 C6 50 08 A4 CF 
			00 9A C7 50 08 C6 50 09 AA 30 C7 50 09 35 01 52 
			12 35 50 52 1B 72 5F 52 1C 35 09 52 1D 35 A2 52 
			13 72 20 9A 1C 52 14 35 01 52 1A 72 14 52 11 72 
			10 52 10 81 3B 00 08 52 02 B7 08 96 5C 35 02 00 
			00 CD 94 02 40 9A 7B 02 5F 97 4F 02 7B 01 90 5F 
			90 97 90 BF 00 01 BA 01 02 C6 00 7F 26 06 B6 08 
			A1 06 27 0D C6 00 60 9A 7F A1 01 26 09 B6 08 A1 
			02 26 03 1C F5 55 5B 02 32 00 08 81 9D 3B 00 08 
			B7 08 CD 9C 64 B6 08 CA 80 9A 54 00 C7 54 00 A6 
			32 B7 00 4A 3D 00 26 F9 72 10 54 01 72 0F 54 00 
			FB 72 1F 54 00 C6 54 05 B7 00 A0 9A C6 54 04 5F 
			97 4F 02 90 5F B6 00 61 BF 00 93 02 BA 00 01 32 
			00 08 81 B7 02 C6 00 91 B7 03 B6 02 C0 9A C1 00 
			92 24 03 C7 00 92 B6 00 C7 00 8F B6 01 C7 00 90 
			B6 00 B1 01 24 03 45 00 01 B6 01 C1 00 92 E0 9A 
			24 05 C7 00 91 20 06 C6 00 92 C7 00 91 C6 00 91 
			B1 03 27 03 A6 05 81 4F 81 A6 02 CD 9A 74 A3 01 
			00 9B 51 25 14 A6 05 CD 9A 74 A3 00 A8 25 0A A6 
			06 CD 9A 74 A3 00 A8 24 09 C6 00 93 4C C7 00 93 
			20 04 20 9B 72 5F 00 93 C6 00 93 A1 0A 25 03 A6 
			01 81 4F 81 3B 00 08 B7 08 27 04 4F CD 9C 83 72 
			1D 50 0C 72 40 9B 1D 50 0D 72 1C 50 0E C6 50 A0 
			A4 CF C7 50 A0 72 18 50 A0 3D 08 27 05 A6 01 CD 
			9C 83 32 00 08 81 60 9B 3B 00 08 B7 08 27 04 4F 
			CD 9C 83 72 15 50 02 72 15 50 03 72 14 50 04 C6 
			50 A0 A4 FC C7 50 A0 72 80 9B 10 50 A0 3D 08 27 
			05 A6 01 CD 9C 83 32 00 08 81 8A 84 A4 BF 88 86 
			CD 98 D5 CD 98 DA C6 00 8C 26 A0 9B 13 C6 00 72 
			26 0B CD 9E 8C 72 5F 00 8D 35 01 00 72 CD 88 80 
			CD 99 11 CD 99 06 80 CD 9D 55 CD 9D C0 9B B7 CD 
			9D D1 CD 9D DE CD 9D F8 CC 9B D2 72 18 50 0F 81 
			72 18 50 11 72 18 50 12 72 19 50 13 72 19 E0 9B 
			50 0F 81 89 FE 90 93 85 5C 5C 90 5D 27 1C 89 FE 
			BF 00 85 5C 5C 89 FE BF 02 85 5C 5C 51 5A 92 D6 
			00 9C 00 92 D7 02 5A 2A F7 51 20 D9 81 72 5F 52 
			62 35 10 52 63 72 5F 52 69 35 08 52 6A 35 68 52 
			5A 35 20 9C 01 52 5D C6 52 6D AA C8 C7 52 6D 72 
			10 52 50 81 3B 00 08 B7 08 20 08 CD 9C 47 B6 08 
			4A B7 08 3D 40 9C 08 26 F4 32 00 08 81 AE 00 F3 
			90 93 5A 90 5D 26 F9 81 9C A2 00 5A 00 45 00 00 
			9B E3 00 35 9E A3 60 9C 00 10 00 00 72 5F 54 00 
			C6 54 01 A4 8F C7 54 01 C6 54 01 C7 54 01 72 13 
			54 01 72 16 54 02 72 10 80 9C 54 01 81 B7 00 27 
			0C C6 00 9E 26 07 9A B6 00 C7 00 9E 81 3D 00 26 
			0A C6 00 9E 27 05 9B 72 5F 00 A0 9C 9E 81 89 FE 
			90 93 85 5C 5C 90 5D 27 12 89 FE BF 00 85 5C 5C 
			51 5A 92 6F 00 5A 2A FA 51 20 E3 81 C0 9C 3B 00 
			08 B7 08 CD 9E 87 4F CD 9D 99 CD 9D DE B6 08 CD 
			95 23 CD 9E 12 32 00 08 81 90 AE 9C 52 20 E0 9C 
			0A 93 1C 00 02 90 FE 90 FD 90 93 90 A3 9C 64 26 
			F0 81 35 CC 50 E0 35 55 50 E0 35 06 50 E1 35 FF 
			00 9D 50 E2 35 AA 50 E0 81 72 5F 53 0E 35 3E 53 
			0F 35 80 53 10 72 1E 53 00 35 01 53 03 81 CD 98 
			AE 52 20 9D 02 BF 08 BE 08 1F 01 96 5C A6 01 CD 
			9E A2 20 F3 AE 03 FF 94 CD 9E 99 5D 27 03 CD 9C 
			DB CD 92 CC 40 9D CC 9E 9C CD 9D 66 CD 9E 61 4F 
			CD 9D C4 CD 9E 38 A6 01 CC 9D C4 72 16 50 02 72 
			16 50 03 72 17 50 60 9D 04 72 16 50 00 81 72 1A 
			50 0C 72 1A 50 0D 72 1B 50 0E 72 1B 50 0A 81 72 
			1F 50 0A 72 1E 50 0C 72 80 9D 1E 50 0D 72 1F 50 
			0E 81 72 14 50 02 72 14 50 03 72 15 50 04 72 15 
			50 00 81 4D 27 08 CD 9C 0B 72 A0 9D 17 50 00 81 
			72 16 50 00 81 89 1E 05 5C 5C 1F 05 5A 5A FE BF 
			00 85 81 72 1B 50 0C 72 1B 50 0D 72 C0 9D 1B 50 
			0E 81 4D 27 05 72 1A 50 0A 81 72 1B 50 0A 81 72 
			1D 50 0C 72 1D 50 0D 72 1D 50 0E 81 72 1F E0 9D 
			50 0C 72 1F 50 0D 72 1F 50 0E 81 4D 27 05 72 1E 
			50 0A 81 72 1F 50 0A 81 72 15 50 02 72 15 50 03 
			00 9E 72 15 50 04 81 4D 27 05 72 14 50 00 81 72 
			15 50 00 81 35 7F 50 D2 35 80 50 D1 35 7F 50 D2 
			81 44 20 9E 44 4E A4 0F 81 47 47 47 47 47 47 81 
			CE 00 60 CD 99 6E FE FE CF 00 60 81 AE 2C E6 90 
			93 5A 90 5D 40 9E 26 F9 81 72 07 50 01 03 A6 01 
			81 4F 81 72 0B 50 0B 03 A6 01 81 4F 81 72 0F 50 
			0B 03 A6 01 81 4F 60 9E 81 A6 18 B7 00 4A 3D 00 
			26 F9 81 9D 9D 8E 9D 9D 81 C6 53 00 A4 01 81 C6 
			53 0D A4 7F 81 35 01 00 80 9E 74 80 35 02 50 C6 
			81 35 AA 50 E0 81 35 01 53 00 81 89 85 CD 9D 1C 
			CC 9E 9F 5F 5C 81 CC 9E 91 9D A0 9E 20 FD 81 00 
			01 00 01 01 00 01 01 00 01 00 00 00 00 00 00 01 
			01 01 01 00 01 01 00 01 00 00 01 00 C0 9E 00 01 
			00 01 00 00 01 01 00 01 00 01 01 FF FF 17 70 03 
			84 03 01 03 03 04 FF FF FF FF FF FF FF FF E0 9F 
			FF FF FF FF FF FF FF FF FF FF FF FF FF FF FF FF 
			FF FF FF FF FF FF FF FF FF FF FF FE D1 34 55 34 
		];
        };
};

&pm8150_gpios {
	gpio1_adc_default: gpio1_adc_default {
			   pins = "gpio3"; /* GPIO3 */
			   function = "normal"; /* normal */
			   bias-high-impedance; /* DISABLE GPIO03 for ADC*/
			   bias-disable;
	};
};

&pm8150l_gpios {
	gpio8_adc_default: gpio8_adc_default {
			   pins = "gpio6"; /* GPIO6 */
			   function = "normal"; /* normal */
			   bias-high-impedance; /* DISABLE GPIO03 for ADC*/
			   bias-disable;
	};
};

&pm7250b_charger {
                        //for smb5:
                        qcom,usb-icl-ua = <1800000>;
                        qcom,fcc-max-ua = <2000000>;
                        qcom,fv-max-uv = <4365000>;
                        qcom,qc3-disable;
                        qcom,hvdcp-disable;
                        //io-channels = <&pm8150b_vadc ADC_GPIO3>;
                        //io-channel-names = "chgID_voltage_adc";
                        //qcom,otg-cl-ua = <2000000>;
                        qcom,float-option = <1>;
                        qcom,oplus-pps-usbpd-detection = <&pm7250b_pdphy>;

                        //for oplus chg framework:
                        qcom,input_current_charger_ma = <2000>;
                        qcom,pd_input_current_charger_ma = <3000>;
                        qcom,qc_input_current_charger_ma = <2000>;

                        qcom,input_current_usb_ma = <500>;

                        qcom,input_current_cdp_ma = <1500>;
                        qcom,input_current_led_ma = <1200>;
                        qcom,input_current_led_ma_high = <1800>;
                        qcom,input_current_led_ma_warm = <1800>;
                        qcom,input_current_led_ma_normal = <2000>;
                        qcom,led_warm_bat_decidegc = <350>;
                        qcom,led_high_bat_decidegc = <370>;

                        qcom,input_current_camera_ma = <1200>;

                        qcom,input_current_vooc_led_ma_high = <1800>;
                        qcom,input_current_vooc_led_ma_warm = <1800>;
                        qcom,input_current_vooc_led_ma_normal = <3600>;
                        qcom,input_current_vooc_ma_normal = <3600>;
                        qcom,vooc_temp_bat_normal_decidegc = <350>;
                        qcom,input_current_vooc_ma_warm = <3200>;
                        qcom,vooc_temp_bat_warm_decidegc = <370>;
                        qcom,input_current_vooc_ma_high = <2200>;
                        qcom,vooc_temp_bat_hot_decidegc = <440>;

                        qcom,charger_current_vooc_ma_normal = <1800>;

                        qcom,chg_ctrl_by_calling;
                        qcom,input_current_calling_ma = <1500>;

                        //qcom,input_current_led_ma_overtemp = <900>;
                        qcom,overtemp_bat_decidegc = <350>;
                        qcom,iterm_disabled = <0>;
                        qcom,iterm_ma = <230>;
                        qcom,recharge-mv = <100>;
                        qcom,batt_capacity_mah = <4320>;/*typical capacity*/
                        //qcom,batt_capacity_mah = <4170>; /*rated capacity*/

                        qcom,removed_bat_decidegc = <190>;  /*<-19C*/

                        qcom,cold_bat_decidegc = <20>;  /*-2C~0C*/
                        qcom,temp_cold_vfloat_mv = <3980>;
                        qcom,temp_cold_fastchg_current_ma = <300>;

                        qcom,little_cold_bat_decidegc = <0>;    /*0C~5C*/
                        qcom,temp_little_cold_vfloat_mv = <4435>;
                        qcom,temp_little_cold_fastchg_current_ma_high = <1850>;
                        qcom,temp_little_cold_fastchg_current_ma_low = <1100>;
                        qcom,temp_little_cold_fastchg_current_ma = <1100>;
                        qcom,pd_temp_little_cold_fastchg_current_ma_high = <1850>;
                        qcom,pd_temp_little_cold_fastchg_current_ma_low = <1100>;
                        qcom,qc_temp_little_cold_fastchg_current_ma_high = <1200>;
                        qcom,qc_temp_little_cold_fastchg_current_ma_low = <950>;

                        qcom,cool_bat_decidegc = <50>;  /*5C~12C*/
                        qcom,temp_cool_vfloat_mv = <4435>;
                        qcom,temp_cool_fastchg_current_ma_high = <2200>;
                        qcom,temp_cool_fastchg_current_ma_low = <1850>;
                        qcom,pd_temp_cool_fastchg_current_ma_high = <2600>;
                        qcom,pd_temp_cool_fastchg_current_ma_low = <1850>;
                        qcom,qc_temp_cool_fastchg_current_ma_high = <1800>;
                        qcom,qc_temp_cool_fastchg_current_ma_low = <1200>;

                        qcom,little_cool_bat_decidegc = <120>;  /*12C~16C*/
                        qcom,temp_little_cool_vfloat_mv = <4435>;
                        qcom,temp_little_cool_fastchg_current_ma = <2200>;
                        qcom,pd_temp_little_cool_fastchg_current_ma = <3000>;
                        qcom,qc_temp_little_cool_fastchg_current_ma = <2000>;

                        qcom,normal_bat_decidegc = <160>;       /*16C~44C*/
                        qcom,temp_normal_fastchg_current_ma = <2200>;
                        qcom,temp_normal_vfloat_mv = <4435>;
                        qcom,pd_temp_normal_fastchg_current_ma = <3000>;
                        qcom,qc_temp_normal_fastchg_current_ma = <2000>;


                        qcom,warm_bat_decidegc = <450>;         /*45C~53C*/ /*8pin Bat Vooc project need add 3 degree C*/
                        qcom,temp_warm_vfloat_mv = <4130>;
                        qcom,temp_warm_fastchg_current_ma = <1100>;
                        qcom,pd_temp_warm_fastchg_current_ma = <1100>;
                        qcom,qc_temp_warm_fastchg_current_ma = <1100>;
                        qcom,temp_warm_fastchg_current_ma_led_on = <500>;

                        qcom,hot_bat_decidegc = <500>;

                        qcom,non_standard_vfloat_mv = <3980>;
                        qcom,non_standard_fastchg_current_ma = <512>;

			qcom,skip_usbtemp_cool_down;

                        //qcom,short_c_bat_cv_mv = <4330>;
                        //qcom,short_c_bat_vfloat_mv = <3800>;
                        //qcom,short_c_bat_fastchg_current_ma = <512>;

                        qcom,cold_vfloat_sw_limit = <3980>;
                        qcom,little_cold_vfloat_sw_limit = <4385>;
                        qcom,cool_vfloat_sw_limit = <4385>;
                        qcom,little_cool_vfloat_sw_limit = <4385>;
                        qcom,normal_vfloat_sw_limit = <4385>;
                        qcom,warm_vfloat_sw_limit = <4080>;
                        qcom,non_standard_vfloat_sw_limit = <3930>;
                        qcom,short_c_bat_vfloat_sw_limit = <3750>;


                        qcom,max_chg_time_sec = <36000>;
                        qcom,charger_hv_thr = <5900>;
                        qcom,charger_recv_thr = <5500>;
                        qcom,charger_lv_thr = <3400>;
                        qcom,vbatt_full_thr = <4475>;
                        qcom,vbatt_hv_thr = <4550>;
                        qcom,vfloat_step_mv = <8>;
                        qcom,non_standard_vfloat_over_sw_limit = <3990>;
                        qcom,cold_vfloat_over_sw_limit = <3990>;
                        qcom,little_cold_vfloat_over_sw_limit = <4445>;
                        qcom,cool_vfloat_over_sw_limit = <4445>;
                        qcom,little_cool_vfloat_over_sw_limit = <4445>;
                        qcom,normal_vfloat_over_sw_limit = <4445>;
                        qcom,warm_vfloat_over_sw_limit = <4140>;

                        qcom,vbatt_power_off = <3250>;
                        qcom,vbatt_soc_1 = <3310>;
                        qcom,vooc_project = <1>;
                        qcom,vbatt_num = <1>;
                        qcom,ffc_support;
                        recharge_after_full;

                        qcom,normal_vterm_hw_inc = <18>;
                        qcom,non_normal_vterm_hw_inc = <18>;

                        qcom,ff1_normal_fastchg_ma = <1100>;
                        qcom,ff1_warm_fastchg_ma = <1100>;
                        qcom,ffc2_normal_fastchg_ma = <350>;/*12C~35c*/
                        qcom,ffc2_temp_warm_decidegc = <350>;
                        qcom,ffc2_warm_fastchg_ma = <400>;/*35C~40c*/
                        qcom,ffc2_temp_high_decidegc = <400>;
                        qcom,ffc2_temp_low_decidegc = <120>;
                        qcom,ffc2_exit_step_ma = <100>;
                        qcom,ff1_exit_step_ma = <550>;
                        qcom,ff1_warm_exit_step_ma = <650>;

                        qcom,ffc_normal_vfloat_sw_limit = <4455>;
                        qcom,ffc2_normal_vfloat_sw_limit = <4445>;
                        qcom,ffc2_warm_vfloat_sw_limit = <4445>;
                        qcom,ffc_temp_normal_vfloat_mv = <4475>;
                        qcom,ffc1_temp_normal_vfloat_mv = <4475>;
                        qcom,ffc2_temp_normal_vfloat_mv = <4500>;
                        qcom,ffc_normal_vfloat_over_sw_limit = <4475>;
                        qcom,ffc1_normal_vfloat_over_sw_limit = <4475>;
                        qcom,ffc2_normal_vfloat_over_sw_limit = <4500>;

                        qcom,default_iterm_ma = <310>;
                        qcom,default_temp_normal_fastchg_current_ma = <2200>;
                        qcom,default_normal_vfloat_sw_limit = <4385>;
                        qcom,default_temp_normal_vfloat_mv = <4435>;
                        qcom,default_normal_vfloat_over_sw_limit = <4445>;

                        qcom,default_temp_little_cool_fastchg_current_ma = <2200>;
                        qcom,default_little_cool_vfloat_sw_limit = <4385>;
                        qcom,default_temp_little_cool_vfloat_mv = <4435>;
                        qcom,default_little_cool_vfloat_over_sw_limit = <4445>;

                        ///qcom,offset_temp = <30>;
                        //for control:
                        //qcom,suspend_after_full;
                        qcom,check_batt_full_by_sw;
                        qcom,external_gauge;
                        qcom,chg_ctrl_by_lcd;
                        //qcom,chg_ctrl_by_vooc;
                        qcom,chg_ctrl_by_camera;
                        qcom,sw_vfloat_over_protect_enable;
                        qcom,lpd-disable;

                        //for PD9V or QC9V
                        qcom,vbatt_pdqc_to_5v_thr = <4180>;

                        qcom,vooc_show_ui_soc_decimal;
                        qcom,ui_soc_decimal_speedmin = <20>;//2A

                        //qcom,chargerid_switch-gpio = <&tlmm 50 0x00>;
                        qcom,ship-gpio = <&pm7250b_gpios 4 0x00>;
                        qcom,ccdetect-gpio = <&tlmm 68 0x00>;
                        //qcom,shortc-gpio = <&tlmm 43 0x00>;
                        qcom,dischg-gpio = <&pm7250b_gpios 7 0x00>;
                        //qcom,charger_int-gpio = <&tlmm 15 0x00>;
                        //qcom,input_pg-gpio = <&tlmm 6 0x00>;
                        //qcom,charger_error-gpio = <&tlmm 118 0x00>;

                        pinctrl-names = "ccdetect_active",
					"ccdetect_sleep",
					"dischg_enable",
					"dischg_disable",
					"ship_active",
					"ship_sleep",
					"gpio1_adc_default",
					"gpio8_adc_default";

                        pinctrl-0 = <&ccdetect_active>;
                        pinctrl-1 = <&ccdetect_sleep>;
                        pinctrl-2 = <&dischg_enable>;
                        pinctrl-3 = <&dischg_disable>;
                        pinctrl-4 = <&ship_active>;
                        pinctrl-5 = <&ship_sleep>;
                        pinctrl-6 = <&gpio1_adc_default>;
                        pinctrl-7 = <&gpio8_adc_default>;
                        //pinctrl-12 = <&gpio5_adc_default>; // aboard - TODO
};

&tlmm {
	ts_int_active: ts_int_active {
		mux {
			pins = "gpio9";
			function = "gpio";
		};
		config {
			pins = "gpio9";
			drive-strength = <8>;
			bias-disable;
		};
	};
	ts_reset_active: ts_reset_active {
		mux {
			pins = "gpio8";
			function = "gpio";
		};
		config {
			pins = "gpio8";
			drive-strength = <8>;
			bias-pull-up;
		};
	};
	ts_reset_suspend: ts_reset_suspend {
		mux {
			pins = "gpio8";
			function = "gpio";
		};
		config {
			pins = "gpio8";
			drive-strength = <8>;
			bias-pull-down;
		};
	};
};

&dsi_sw43404_amoled_video {
	qcom,panel-supply-entries = <&dsi_panel_pwr_supply>;
	qcom,mdss-dsi-bl-pmic-control-type = "bl_ctrl_dcs";
	qcom,mdss-dsi-bl-min-level = <1>;
	qcom,mdss-dsi-bl-max-level = <1023>;
	qcom,mdss-brightness-max-level = <255>;
	qcom,platform-te-gpio = <&tlmm 10 0>;
	qcom,platform-reset-gpio = <&pm8150l_gpios 3 0>;
};

&dsi_sw43404_amoled_cmd {
	qcom,panel-supply-entries = <&dsi_panel_pwr_supply>;
	qcom,mdss-dsi-bl-pmic-control-type = "bl_ctrl_dcs";
	qcom,mdss-dsi-bl-min-level = <1>;
	qcom,mdss-dsi-bl-max-level = <1023>;
	qcom,mdss-brightness-max-level = <255>;
	qcom,platform-te-gpio = <&tlmm 10 0>;
	qcom,platform-reset-gpio = <&pm8150l_gpios 3 0>;
};

&dsi_sw43404_amoled_fhd_plus_cmd {
	qcom,panel-supply-entries = <&dsi_panel_pwr_supply>;
	qcom,mdss-dsi-bl-pmic-control-type = "bl_ctrl_dcs";
	qcom,mdss-dsi-bl-min-level = <1>;
	qcom,mdss-dsi-bl-max-level = <1023>;
	qcom,mdss-brightness-max-level = <255>;
	qcom,platform-te-gpio = <&tlmm 10 0>;
	qcom,platform-reset-gpio = <&pm8150l_gpios 3 0>;
};

&sde_dsi {
	qcom,dsi-default-panel = <&dsi_sw43404_amoled_video>;
};

/* Add for NXP NFCC */
&qupv3_se0_i2c {
        status = "ok";
        //qcom,clk-freq-out = <1000000>;
    nq@28 {
        compatible = "nxp,pn544";
        reg = <0x28>;
        nxp,pn544-irq = <&tlmm 34 0x00>;
        nxp,pn544-ven = <&tlmm 12 0x00>;
        nxp,pn544-fw-dwnld = <&tlmm 35 0x00>;
        nxp,pn544-clk-gpio = <&tlmm 31 0x00>;
        nxp,pn544-ese-pwr = <&tlmm 26 0x00>;
        //nfc_voltage_s4-supply = <&pm8150_s4>;
        interrupt-parent = <&tlmm>;
        //qcom,clk-src = "BBCLK3";
        interrupts = <34 0>;
        interrupt-names = "nfc_irq";
        pinctrl-names = "nfc_active", "nfc_suspend";
        pinctrl-0 = <&nfc_int_active &nfc_enable_active>;
        pinctrl-1 = <&nfc_int_suspend &nfc_enable_suspend>;
    };
};

/* Add for NXP eSE */
&qupv3_se1_spi {
    status = "ok";
        //qcom,disable-autosuspend;

    ese@0 {
        compatible = "nxp,p61";
        reg = <0>;
        spi-max-frequency = <8000000>;
        nxp,nfcc = "5-0028";
    };
};

&dsi_sim_cmd {
	qcom,panel-supply-entries = <&dsi_panel_pwr_supply>;
	qcom,mdss-dsi-bl-pmic-control-type = "bl_ctrl_dcs";
	qcom,platform-reset-gpio = <&pm8150l_gpios 3 0>;
};

&dsi_sim_vid {
	qcom,panel-supply-entries = <&dsi_panel_pwr_supply>;
	qcom,mdss-dsi-bl-pmic-control-type = "bl_ctrl_dcs";
	qcom,platform-reset-gpio = <&pm8150l_gpios 3 0>;
};

&dsi_dual_sim_cmd {
	qcom,panel-supply-entries = <&dsi_panel_pwr_supply>;
	qcom,mdss-dsi-bl-pmic-control-type = "bl_ctrl_dcs";
	qcom,platform-reset-gpio = <&pm8150l_gpios 3 0>;
};

&dsi_dual_sim_vid {
	qcom,panel-supply-entries = <&dsi_panel_pwr_supply>;
	qcom,mdss-dsi-bl-pmic-control-type = "bl_ctrl_dcs";
	qcom,platform-reset-gpio = <&pm8150l_gpios 3 0>;
};


&L6P {
	regulator-max-microvolt = <2800000>;
	/* Reduced the headroom by 16mV for AHC */
	qcom,min-dropout-voltage = <184000>;
};

&L7P {
	regulator-max-microvolt = <2900000>;
	/* Reduced the headroom by 16mV for AHC */
	qcom,min-dropout-voltage = <200000>;
};
